# STM32H503 register map
File version: 0.3
CPU: CM33 r0p0, little endian, MPU, FPU, 4 interrupt priority bits
Registers are 32-bit, read-write, reset 0x0 unless marked. A register's access mark holds for its fields unless they carry their own. Offsets are from the block's base; [hi:lo] are bit positions.

## RNG — True random number generator
Base 0x420C0800
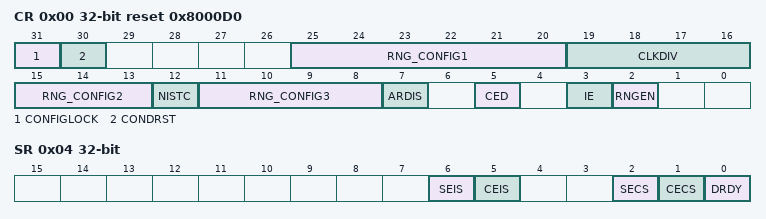
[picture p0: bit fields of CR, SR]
0x00 CR reset 0x8000D0 — RNG control register
  [31] CONFIGLOCK — RNG Config lock This bitfield is set once: if this bit is set it can only be reset to 0 if RNG is reset.
  [30] CONDRST — Conditioning soft reset Write 1 and then write 0 to reset the conditioning logic, clear all the FIFOs and start a new RNG initialization process, with RNG_SR cleared. Registers RNG_CR and RNG_NSCR are not changed by CONDRST. This bit must be set to 1 in the same access that set any configuration bits [29:4]. In other words, when CONDRST bit is set to 1 correct configuration in bits [29:4] must also be written. When CONDRST is set to 0 by software its value goes to 0 when the reset process is done. It takes about 2 AHB clock cycles + 2 RNG clock cycles.
  [25:20] RNG_CONFIG1 — RNG configuration 1 Reserved to the RNG configuration (bitfield 1). Must be initialized using the recommended value documented in Section 23.6: RNG entropy source validation. Writing any bit of RNG_CONFIG1 is taken into account only if CONDRST bit is set to 1 in the same access, while CONFIGLOCK remains at 0. Writing to this bit is ignored if CONFIGLOCK = 1.
  [19:16] CLKDIV — Clock divider factor This value used to configure an internal programmable divider (from 1 to 16) acting on the incoming RNG clock. These bits can be written only when the core is disabled (RNGEN = 0). ... Writing these bits is taken into account only if CONDRST bit is set to 1 in the same access, while CONFIGLOCK remains at 0. Writing to this bit is ignored if CONFIGLOCK = 1.
  [15:13] RNG_CONFIG2 — RNG configuration 2 Reserved to the RNG configuration (bitfield 2). Refer to RNG_CONFIG1 bitfield for details.
  [12] NISTC — Non NIST compliant two conditioning loops are performed and 256 bits of noise source are used. Writing this bit is taken into account only if CONDRST bit is set to 1 in the same access, while CONFIGLOCK remains at 0. Writing to this bit is ignored if CONFIGLOCK = 1.
  [11:8] RNG_CONFIG3 — RNG configuration 3 Reserved to the RNG configuration (bitfield 3). Refer to RNG_CONFIG1 bitfield for details. If NISTC bit is cleared in this register RNG_CONFIG3 bitfield values are ignored by RNG.
  [7] ARDIS — Auto reset disable When auto-reset is enabled application still need to clear SEIS bit after a noise source error. Writing this bit is taken into account only if CONDRST bit is set to 1 in the same access, while CONFIGLOCK remains at 0. Writing to this bit is ignored if CONFIGLOCK = 1.
  [5] CED — Clock error detection The clock error detection cannot be enabled nor disabled on-the-fly when the RNG is enabled, i.e. to enable or disable CED the RNG must be disabled. Writing this bit is taken into account only if CONDRST bit is set to 1 in the same access, while CONFIGLOCK remains at 0. Writing to this bit is ignored if CONFIGLOCK = 1.
  [3] IE — Interrupt Enable
  [2] RNGEN — True random number generator enable
0x04 SR access per field — RNG status register
  [6] SEIS rw — Seed error interrupt status This bit is set at the same time as SECS. It is cleared by writing 0 (unless CONDRST is used). Writing 1 has no effect. An interrupt is pending if IE = 1 in the RNG_CR register.
  [5] CEIS rw — Clock error interrupt status This bit is set at the same time as CECS. It is cleared by writing 0. Writing 1 has no effect. An interrupt is pending if IE = 1 in the RNG_CR register.
  [2] SECS ro — Seed error current status Run-time repetition count test failed (noise source has provided more than 24 consecutive bits at a constant value 0 or 1, or more than 32 consecutive occurrence of two bits patterns 01 or 10) Start-up or continuous adaptive proportion test on noise source failed. Start-up post-processing/conditioning sanity check failed.
  [1] CECS ro — Clock error current status Note: CECS bit is valid only if the CED bit in the RNG_CR register is set to 0.
  [0] DRDY ro — Data Ready Once the output buffer becomes empty (after reading the RNG_DR register), this bit returns to 0 until a new random value is generated. Note: The DRDY bit can rise when the peripheral is disabled (RNGEN = 0 in the RNG_CR register). If IE=1 in the RNG_CR register, an interrupt is generated when DRDY = 1.
0x08 DR ro — RNG data register
  [31:0] RNDATA — Random data 32-bit random data which are valid when DRDY = 1. When DRDY = 0 RNDATA value is zero. It is recommended to always verify that RNG_DR is different from zero. Because when it is the case a seed error occurred between RNG_SR polling and RND_DR output reading (rare event).
0x10 HTCR reset 0x72AC — RNG health test control register
  [31:0] HTCFG — health test configuration This configuration is used by RNG to configure the health tests. See Section 23.6: RNG entropy source validation for the recommended value. Note: The RNG behavior, including the read to this register, is not guaranteed if a different value from the recommended value is written.
